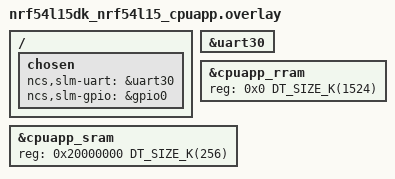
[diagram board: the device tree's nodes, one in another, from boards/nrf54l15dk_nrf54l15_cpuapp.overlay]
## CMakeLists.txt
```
#
# Copyright (c) 2020 Nordic Semiconductor ASA
#
# SPDX-License-Identifier: LicenseRef-Nordic-5-Clause
#
cmake_minimum_required(VERSION 3.20.0)

find_package(Zephyr REQUIRED HINTS $ENV{ZEPHYR_BASE})

project(openthread_cellular_mesh_meter)

# NORDIC SDK APP START
target_sources(app PRIVATE src/main.c
			   src/coap_utils.c)
# NORDIC SDK APP END

target_sources_ifdef(CONFIG_MODEM_UTILS_SIMULATED app PRIVATE src/modem_utils_simulated.c)
target_sources_ifdef(CONFIG_MODEM_UTILS_SERIAL_LTE_MODEM app PRIVATE src/modem_utils_slm.c)

target_sources_ifdef(CONFIG_BT_NUS app PRIVATE src/ble_utils.c)
```

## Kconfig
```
#
# Copyright (c) 2020 Nordic Semiconductor ASA
#
# SPDX-License-Identifier: LicenseRef-Nordic-5-Clause
#

menu "Zephyr Kernel"
source "Kconfig.zephyr"
endmenu

config MODEM_UTILS_SIMULATED
	bool "Simulated modem utilities"
	help
	  When enabled, the modem utilities will be simulated.

config MODEM_UTILS_SERIAL_LTE_MODEM
	bool "Serial LTE modem utilities"
	help
	  When enabled, the modem utilities will be using the serial LTE modem.

module = CELLULAR_MESH_METER
module-str = Cellular mesh meter
source "${ZEPHYR_BASE}/subsys/logging/Kconfig.template.log_config"

module = CELLULAR_MESH_METER_UTILS
module-str = Cellular mesh meter utilities
source "${ZEPHYR_BASE}/subsys/logging/Kconfig.template.log_config"

module = BLE_UTILS
module-str = Bluetooth connection utilities
source "${ZEPHYR_BASE}/subsys/logging/Kconfig.template.log_config"

module = MODEM_UTILS
module-str = Modem link utilities
source "${ZEPHYR_BASE}/subsys/logging/Kconfig.template.log_config"
```

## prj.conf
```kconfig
#
# Copyright (c) 2020 Nordic Semiconductor
#
# SPDX-License-Identifier: LicenseRef-Nordic-5-Clause
#

# nRF board library
CONFIG_DK_LIBRARY=y

# Enable CoAP utils and CoAP protocol
CONFIG_COAP=y
CONFIG_COAP_UTILS=y

# Generic networking options
CONFIG_NETWORKING=y

# L2 OpenThread enabling
CONFIG_NET_L2_OPENTHREAD=y

# Network shell
CONFIG_SHELL=y
CONFIG_OPENTHREAD_SHELL=y
CONFIG_SHELL_ARGC_MAX=26
CONFIG_SHELL_CMD_BUFF_SIZE=416

# Increase Settings storage size
CONFIG_PM_PARTITION_SIZE_SETTINGS_STORAGE=0x8000

# Network sockets
CONFIG_NET_SOCKETS=y
CONFIG_POSIX_API=y
CONFIG_NET_SOCKETS_POLL_MAX=4

# Same network Master Key for client and server
CONFIG_OPENTHREAD_NETWORKKEY="00:11:22:33:44:55:66:77:88:99:aa:bb:cc:dd:ee:ff"

CONFIG_MBEDTLS_SHA1_C=n
CONFIG_FPU=y

# Enable OpenThread CoAP support API
CONFIG_OPENTHREAD_COAP=y

CONFIG_SHELL_WILDCARD=n
CONFIG_SHELL_ARGC_MAX=40
CONFIG_SHELL_CMD_BUFF_SIZE=1024
CONFIG_SHELL_STACK_SIZE=2048

CONFIG_SERIAL=y
CONFIG_UART_ASYNC_API=y

CONFIG_MODEM_SLM=y
CONFIG_MODEM_SLM_SHELL=n

CONFIG_MODEM_UTILS_SERIAL_LTE_MODEM=y

CONFIG_OPENTHREAD_SOURCES=y
CONFIG_OPENTHREAD_COAP_BLOCK=y
CONFIG_OPENTHREAD_THREAD_STACK_SIZE=8192
```

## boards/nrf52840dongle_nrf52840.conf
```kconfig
#
# Copyright (c) 2024 Nordic Semiconductor
#
# SPDX-License-Identifier: LicenseRef-Nordic-5-Clause
#

CONFIG_SHELL_BACKEND_SERIAL_INIT_PRIORITY=51

CONFIG_USB_CDC_ACM_LOG_LEVEL_OFF=y

CONFIG_USB_DEVICE_MANUFACTURER="Nordic Semiconductor ASA"
CONFIG_USB_DEVICE_PRODUCT="Thread CLI"
CONFIG_USB_DEVICE_VID=0x1915
CONFIG_USB_DEVICE_PID=0x0000

# Enable resetting to Bootloader using GPIO
CONFIG_OPENTHREAD_PLATFORM_BOOTLOADER_MODE_GPIO=y

CONFIG_MODEM_SLM=n
CONFIG_MODEM_UTILS_SERIAL_LTE_MODEM=n
CONFIG_MODEM_UTILS_SIMULATED=y
```

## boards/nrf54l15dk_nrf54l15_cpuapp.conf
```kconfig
#
# Copyright (c) 2024 Nordic Semiconductor
#
# SPDX-License-Identifier: LicenseRef-Nordic-5-Clause
#

# Disable the unsupported driver
CONFIG_NRFX_UARTE0=n

# Increase Main and shell stack sizes to avoid stack overflow
# while using CRACEN
CONFIG_MAIN_STACK_SIZE=6144
CONFIG_SHELL_STACK_SIZE=5120

# Workaround required as Zephyr L2 implies usage of NVS backend for settings.
# It should be removed once the proper fix will be applied in Zephyr.
CONFIG_NVS=n
CONFIG_ZMS=y
CONFIG_SETTINGS_ZMS=y

CONFIG_NRFX_UARTE30=y
CONFIG_UART_30_INTERRUPT_DRIVEN=n
CONFIG_UART_30_ASYNC=y
CONFIG_MODEM_SLM_POWER_PIN=4
#CONFIG_MODEM_SLM_INDICATE_PIN=13
CONFIG_MODEM_SLM_SHELL=y
```

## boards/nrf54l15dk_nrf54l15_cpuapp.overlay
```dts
/*
 * Copyright (c) 2024 Nordic Semiconductor ASA
 *
 * SPDX-License-Identifier: LicenseRef-Nordic-5-Clause
 */

/ {
	chosen {
		ncs,slm-uart = &uart30;
		ncs,slm-gpio = &gpio0;
	};
};

&uart30 {
	status = "okay";
};

// restore full RRAM and SRAM space - by default some parts are dedicated to FLPR
&cpuapp_rram {
	reg = <0x0 DT_SIZE_K(1524)>;
};

&cpuapp_sram {
	reg = <0x20000000 DT_SIZE_K(256)>;
	ranges = <0x0 0x20000000  DT_SIZE_K(256)>;
};
```

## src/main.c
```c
/*
 * Copyright (c) 2020 Nordic Semiconductor ASA
 *
 * SPDX-License-Identifier: LicenseRef-Nordic-5-Clause
 */

#include <zephyr/kernel.h>
#include <dk_buttons_and_leds.h>
#include <zephyr/logging/log.h>
#include <ram_pwrdn.h>
#include <zephyr/device.h>
#include <zephyr/pm/device.h>

#include "coap_utils.h"
#include "modem_utils.h"

#if CONFIG_BT_NUS
#include "ble_utils.h"
#endif

#include <zephyr/drivers/uart.h>
#include <zephyr/usb/usb_device.h>

LOG_MODULE_REGISTER(cellular_mesh_meter, CONFIG_CELLULAR_MESH_METER_LOG_LEVEL);

#define OT_CONNECTION_LED	DK_LED1
#define BLE_CONNECTION_LED	DK_LED2
#define MODEM_IDLE_LED		DK_LED3
#define MODEM_BUSY_LED		DK_LED4

#define DEFAULT_MEASURE_CNT 10
#define MEASURE_BLOCK_SIZE 512
#define UPLOAD_MEASUREMENT_TIMEOUT		K_MSEC(100)
#define UPLOAD_MEASUREMENT_RETRY_LIMIT	100

static bool uploading_measurement = false;
static uint16_t uploading_measurement_retry_count = 0;
static struct k_work_delayable uploading_measurement_work;
static uint32_t max_block_count = DEFAULT_MEASURE_CNT;

#if CONFIG_BT_NUS

#define COMMAND_UPLOAD_MEASUREMENT  'u'
#define COMMAND_CHANGE_UPLOAD_COUNT 'c'

int upload_measurement(void);

static void on_nus_received(struct bt_conn *conn, const uint8_t *const data, uint16_t len)
{
	LOG_INF("Received data: %c", data[0]);

	switch (*data) {
	case COMMAND_UPLOAD_MEASUREMENT:
		upload_measurement();
		break;
	
	case COMMAND_CHANGE_UPLOAD_COUNT:
		if (len > 1) {
			max_block_count = atoi((const char *)&data[1]);
		} else {
			LOG_WRN("Invalid data length");
		}
		break;

	default:
		LOG_WRN("Received invalid data from NUS");
	}
}

static void on_ble_connect(struct k_work *item)
{
	ARG_UNUSED(item);

	dk_set_led_on(BLE_CONNECTION_LED);
}

static void on_ble_disconnect(struct k_work *item)
{
	ARG_UNUSED(item);

	dk_set_led_off(BLE_CONNECTION_LED);
}

#endif /* CONFIG_BT_NUS */

static void on_ot_connect(struct k_work *item)
{
	ARG_UNUSED(item);

	dk_set_led_on(OT_CONNECTION_LED);
}

static void on_ot_disconnect(struct k_work *item)
{
	ARG_UNUSED(item);

	dk_set_led_off(OT_CONNECTION_LED);
}

static void on_button_changed(uint32_t button_state, uint32_t has_changed)
{
	uint32_t buttons = button_state & has_changed;

	if (buttons & DK_BTN1_MSK) {
		upload_measurement();
	}

	if (buttons & DK_BTN2_MSK) {
	}

	if (buttons & DK_BTN3_MSK) {
	}

	if (buttons & DK_BTN4_MSK) {
	}
}

static void on_modem_request(otMessage *message, const otMessageInfo *message_info)
{
	uint8_t command;
	modem_state current_modem_state = MODEM_STATE_OFF, remote_modem_state = MODEM_STATE_OFF;

	current_modem_state = modem_get_state();

	if (otMessageRead(message, otMessageGetOffset(message), &command,
		sizeof(command)) != sizeof(command)) {
		LOG_ERR("Modem handler - Missing modem command");
	}

	char ip_addr_from[OT_IP6_ADDRESS_STRING_SIZE], ip_addr_to[OT_IP6_ADDRESS_STRING_SIZE];

	otIp6AddressToString(&(message_info->mPeerAddr), ip_addr_from, sizeof(ip_addr_from));
	otIp6AddressToString(&(message_info->mSockAddr), ip_addr_to, sizeof(ip_addr_to));

	LOG_HEXDUMP_INF(ip_addr_from, strlen(ip_addr_from), "coap request from ");
	LOG_HEXDUMP_INF(ip_addr_to, strlen(ip_addr_to), "coap request to ");
	LOG_INF("Got command: %d", command);

	switch (command) {
	case MODEM_COMMAND_DISCOVER:
		if ((current_modem_state == MODEM_STATE_IDLE ) || (current_modem_state == MODEM_STATE_BUSY)) {
			otMessageInfo report_state_message_info;
			memset(&report_state_message_info, 0, sizeof(report_state_message_info));
			report_state_message_info.mPeerAddr = message_info->mPeerAddr;
			report_state_message_info.mPeerPort = COAP_PORT;
			coap_utils_modem_report_state(&report_state_message_info, current_modem_state);
		} else {	//MODEM_STATE_OFF
			LOG_INF("Modem is off");
		}
		break;

	case MODEM_COMMAND_REPORT_STATE:
		if (otMessageRead(message, otMessageGetOffset(message) + sizeof(command),
			&remote_modem_state, sizeof(remote_modem_state)) != sizeof(remote_modem_state)) {
			LOG_ERR("Missing modem state of the remote modem");
		} else {
			LOG_INF("Remote modem state: %d", remote_modem_state);
			coap_utils_modem_report_state_response(message, message_info);
			if ((remote_modem_state == MODEM_STATE_IDLE) && (uploading_measurement == false)) {
				otMessageInfo upload_measurement_message_info;

				uploading_measurement = true;
				memset(&upload_measurement_message_info, 0, sizeof(upload_measurement_message_info));
				upload_measurement_message_info.mPeerAddr = message_info->mPeerAddr;
				upload_measurement_message_info.mPeerPort = COAP_PORT;
				coap_utils_modem_upload_measurement(&upload_measurement_message_info);
			}
		}
		break;

	case MODEM_COMMAND_UPLOAD_MEASUREMENT:
		LOG_INF("Receive Upload Measurement command");
		if (current_modem_state == MODEM_STATE_IDLE) {
			LOG_INF("Modem is idle, start uploading measurement");
			modem_set_state(MODEM_STATE_BUSY);
			coap_utils_send_response(message, message_info, OT_COAP_CODE_CHANGED);
		} else {
			LOG_INF("Modem is busy, wait for next round");
			coap_utils_send_response(message, message_info, OT_COAP_CODE_SERVICE_UNAVAILABLE);
		}
		break;

	default:
		break;
	}
}

static void on_meter_block_tx(void *context,
							  uint8_t *block,
							  uint32_t position,
							  uint16_t *block_length,
							  bool *more)
{
	static uint32_t block_count = 0;
	ARG_UNUSED(position);

	LOG_INF("send block: Num %i Len %i pos: %i", block_count, *block_length, position);
	/* Fill tx block with ascii 0 ~ 9 */
	for (uint16_t i = 0; i < *block_length; i++) {
		block[i] = 48 + i % 10;
	}
	LOG_HEXDUMP_INF(block, *block_length, "Sent block:");
	if (block_count == max_block_count - 1)
	{
		block_count = 0;
		*more     = false;
	}
	else
	{
		*more = true;
		block_count++;
	}
}

static otError on_meter_block_rx(void *context,
								 const uint8_t *block,
								 uint32_t position,
								 uint16_t block_length,
								 bool more,
								 uint32_t total_length)
{
	ARG_UNUSED(total_length);
	int ret;

	LOG_INF("received block: Num %i Len %i more: %d", position / block_length, block_length, more);
	LOG_HEXDUMP_INF(block, block_length, "Received block:");
	ret = modem_cloud_upload_data(block, (size_t)block_length);
	if (ret != 0) {
		if (ret == -EBUSY) {
			LOG_DBG("Modem is busy, wait for next round");
			return OT_ERROR_BUSY;
		} else if (ret == -ENOMEM) {
			LOG_ERR("No memory to upload data");
			return OT_ERROR_NO_BUFS;
		} else {
			LOG_ERR("Fail to upload data to cloud");
			return OT_ERROR_FAILED;
		}
	}
	if (more == false) {
		LOG_INF("Received all blocks");
		modem_set_state(MODEM_STATE_IDLE);
	}
	return OT_ERROR_NONE;
}

static void on_meter_response(void *context, otMessage *message, const otMessageInfo *message_info, otError error)
{
	if (error != OT_ERROR_NONE)
	{
		LOG_ERR("coap receive response error %d: %s", error, otThreadErrorToString(error));
	}
	/* Upload finiched */
	uploading_measurement = false;
	LOG_INF("Upload finished");
	return;
}

static void on_modem_state_change(modem_state state)
{
	dk_set_led_off(MODEM_IDLE_LED);
	dk_set_led_off(MODEM_BUSY_LED);

	switch (state) {
	case MODEM_STATE_IDLE:
		dk_set_led_on(MODEM_IDLE_LED);
		break;

	case MODEM_STATE_BUSY:
		dk_set_led_on(MODEM_BUSY_LED);
		break;
	default:
		break;
	}
}

void uploading_measurement_handler(struct k_work *work)
{
	static uint32_t block_count = 0;

	if (uploading_measurement) {
		uint8_t block[MEASURE_BLOCK_SIZE];
		int ret;

		/* Fill tx block with ascii 0 ~ 9 */
		for (uint16_t i = 0; i < MEASURE_BLOCK_SIZE; i++) {
			block[i] = 48 + i % 10;
		}
		ret = modem_cloud_upload_data(block, MEASURE_BLOCK_SIZE);
		if (ret != 0) {
			if (ret == -EBUSY) {
				uploading_measurement_retry_count++;
				if (uploading_measurement_retry_count > UPLOAD_MEASUREMENT_RETRY_LIMIT) {
					LOG_ERR("Retry limit reached");
					goto error;
				}
				LOG_DBG("Modem is busy, wait for next round");
				k_work_schedule(&uploading_measurement_work, UPLOAD_MEASUREMENT_TIMEOUT);
			} else if (ret == -ENOMEM) {
				LOG_ERR("No memory to upload data");
				goto error;
			} else {
				LOG_ERR("Fail to upload data to cloud");
				goto error;
			}
		} else {
			LOG_INF("Sent block: Num %i Len %i", block_count, MEASURE_BLOCK_SIZE);
			uploading_measurement_retry_count = 0;
			if (block_count == max_block_count - 1) {
				block_count = 0;
				uploading_measurement = false;
				modem_set_state(MODEM_STATE_IDLE);
			} else {
				block_count++;
				k_work_schedule(&uploading_measurement_work, UPLOAD_MEASUREMENT_TIMEOUT);
			}
		}
	}
	return;
error:
	block_count = 0;
	uploading_measurement = false;
	uploading_measurement_retry_count = 0;
	return;
}

int upload_measurement(void)
{
	if (uploading_measurement) {
		LOG_INF("Already uploading measurement");
		return -EBUSY;
	}

	if (modem_get_state() == MODEM_STATE_IDLE) {
		LOG_INF("Modem is idle, start uploading measurement");
		modem_set_state(MODEM_STATE_BUSY);
		uploading_measurement = true;
		k_work_schedule(&uploading_measurement_work, K_NO_WAIT);
	} else if (modem_get_state() == MODEM_STATE_BUSY) {
		LOG_INF("Modem is busy, wait for next round");
		return -EBUSY;
	} else {
		LOG_INF("Modem is off. Ask remote modem to upload measurement");
		coap_utils_modem_discover();
	}

	return 0;
}

int main(void)
{
	int ret;

	LOG_INF("Start Cellular Mesh Meter sample");

	if (IS_ENABLED(CONFIG_RAM_POWER_DOWN_LIBRARY)) {
		power_down_unused_ram();
	}

	ret = dk_buttons_init(on_button_changed);
	if (ret) {
		LOG_ERR("Cannot init buttons (error: %d)", ret);
		return 0;
	}

	ret = dk_leds_init();
	if (ret) {
		LOG_ERR("Cannot init leds, (error: %d)", ret);
		return 0;
	}

#if CONFIG_BT_NUS
	struct bt_nus_cb nus_clbs = {
		.received = on_nus_received,
		.sent = NULL,
	};

	ret = ble_utils_init(&nus_clbs, on_ble_connect, on_ble_disconnect);
	if (ret) {
		LOG_ERR("Cannot init BLE utilities");
		return 0;
	}

#endif /* CONFIG_BT_NUS */

#if DT_NODE_HAS_COMPAT(DT_CHOSEN(zephyr_shell_uart), zephyr_cdc_acm_uart)
	const struct device *dev;
	uint32_t dtr = 0U;

	ret = usb_enable(NULL);
	if (ret != 0 && ret != -EALREADY) {
		LOG_ERR("Failed to enable USB");
		return 0;
	}

	dev = DEVICE_DT_GET(DT_CHOSEN(zephyr_shell_uart));
	if (dev == NULL) {
		LOG_ERR("Failed to find specific UART device");
		return 0;
	}

	LOG_INF("Waiting for host to be ready to communicate");

	/* Data Terminal Ready - check if host is ready to communicate */
	while (!dtr) {
		ret = uart_line_ctrl_get(dev, UART_LINE_CTRL_DTR, &dtr);
		if (ret) {
			LOG_ERR("Failed to get Data Terminal Ready line state: %d",
				ret);
			continue;
		}
		k_msleep(100);
	}

	/* Data Carrier Detect Modem - mark connection as established */
	(void)uart_line_ctrl_set(dev, UART_LINE_CTRL_DCD, 1);
	/* Data Set Ready - the NCP SoC is ready to communicate */
	(void)uart_line_ctrl_set(dev, UART_LINE_CTRL_DSR, 1);
#endif

	k_work_init_delayable(&uploading_measurement_work, uploading_measurement_handler);

	ret = ot_coap_init(&on_modem_request, &on_meter_block_tx, &on_meter_block_rx, &on_meter_response);
	if (ret) {
		LOG_ERR("Could not initialize OpenThread CoAP");
	}
	coap_client_utils_init(on_ot_connect, on_ot_disconnect);

	ret = modem_init(on_modem_state_change);
	if (ret) {
		LOG_ERR("Cannot init modem (error: %d)", ret);
		return ret;
	}

	return 0;
}
```

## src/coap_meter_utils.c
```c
/*
 * Copyright (c) 2020 Nordic Semiconductor ASA
 *
 * SPDX-License-Identifier: LicenseRef-Nordic-5-Clause
 */

#include <zephyr/kernel.h>
#include <net/coap_utils.h>
#include <zephyr/logging/log.h>
#include <zephyr/net/openthread.h>
#include <zephyr/net/socket.h>

#include "coap_meter_utils.h"

LOG_MODULE_REGISTER(cellular_mesh_meter_util, CONFIG_CELLULAR_MESH_METER_UTILS_LOG_LEVEL);

#define RESPONSE_POLL_PERIOD 100

static uint32_t poll_period;

static bool is_connected;

#define COAP_WORKQ_STACK_SIZE 2048
#define COAP_WORKQ_PRIORITY 5

K_THREAD_STACK_DEFINE(coap_client_workq_stack_area, COAP_WORKQ_STACK_SIZE);
static struct k_work_q coap_client_workq;

static struct k_work toggle_MTD_SED_work;
static struct k_work modem_discover_work;
static struct k_work on_connect_work;
static struct k_work on_disconnect_work;

mtd_mode_toggle_cb_t on_mtd_mode_toggle;

/* Options supported by the server */
static const char *const modem_option[] = { MODEM_URI_PATH, NULL };
static const char *const provisioning_option[] = { PROVISIONING_URI_PATH,
						   NULL };

/* Thread multicast mesh local address */
static struct sockaddr_in6 multicast_local_addr = {
	.sin6_family = AF_INET6,
	.sin6_port = htons(COAP_PORT),
	.sin6_addr.s6_addr = { 0xff, 0x03, 0x00, 0x00, 0x00, 0x00, 0x00, 0x00,
			       0x00, 0x00, 0x00, 0x00, 0x00, 0x00, 0x00, 0x01 },
	.sin6_scope_id = 0U
};

/* Variable for storing server address acquiring in provisioning handshake */
static char unique_local_addr_str[INET6_ADDRSTRLEN];
static struct sockaddr_in6 unique_local_addr = {
	.sin6_family = AF_INET6,
	.sin6_port = htons(COAP_PORT),
	.sin6_addr.s6_addr = {0, },
	.sin6_scope_id = 0U
};

struct server_context {
	struct otInstance *ot;
	bool provisioning_enabled;
	modem_request_callback_t on_modem_request;
	provisioning_request_callback_t on_provisioning_request;
};

static struct server_context srv_context = {
	.ot = NULL,
	.provisioning_enabled = false,
	.on_modem_request = NULL,
	.on_provisioning_request = NULL,
};

/**@brief Definition of CoAP resources for provisioning. */
static otCoapResource provisioning_resource = {
	.mUriPath = PROVISIONING_URI_PATH,
	.mHandler = NULL,
	.mContext = NULL,
	.mNext = NULL,
};

/**@brief Definition of CoAP resources for modem. */
static otCoapResource modem_resource = {
	.mUriPath = MODEM_URI_PATH,
	.mHandler = NULL,
	.mContext = NULL,
	.mNext = NULL,
};

static otError provisioning_response_send(otMessage *request_message,
					  const otMessageInfo *message_info)
{
	otError error = OT_ERROR_NO_BUFS;
	otMessage *response;
	const void *payload;
	uint16_t payload_size;

	response = otCoapNewMessage(srv_context.ot, NULL);
	if (response == NULL) {
		goto end;
	}

	otCoapMessageInit(response, OT_COAP_TYPE_NON_CONFIRMABLE,
			  OT_COAP_CODE_CONTENT);

	error = otCoapMessageSetToken(
		response, otCoapMessageGetToken(request_message),
		otCoapMessageGetTokenLength(request_message));
	if (error != OT_ERROR_NONE) {
		goto end;
	}

	error = otCoapMessageSetPayloadMarker(response);
	if (error != OT_ERROR_NONE) {
		goto end;
	}

	payload = otThreadGetMeshLocalEid(srv_context.ot);
	payload_size = sizeof(otIp6Address);

	error = otMessageAppend(response, payload, payload_size);
	if (error != OT_ERROR_NONE) {
		goto end;
	}

	error = otCoapSendResponse(srv_context.ot, response, message_info);

	LOG_HEXDUMP_INF(payload, payload_size, "Sent provisioning response:");

end:
	if (error != OT_ERROR_NONE && response != NULL) {
		otMessageFree(response);
	}

	return error;
}

otError coap_server_send_modem_update_state_response(otMessage *request_message,
					  const otMessageInfo *message_info)
{
	otError error = OT_ERROR_NO_BUFS;
	otMessage *response;

	response = otCoapNewMessage(srv_context.ot, NULL);
	if (response == NULL) {
		goto end;
	}

	error = otCoapMessageInitResponse(response, request_message, OT_COAP_TYPE_ACKNOWLEDGMENT,
									  OT_COAP_CODE_CHANGED);
	if (error != OT_ERROR_NONE) {
		goto end;
	}

	error = otCoapSendResponse(srv_context.ot, response, message_info);

end:
	if (error != OT_ERROR_NONE && response != NULL) {
		otMessageFree(response);
	}

	return error;
}

void handle_modem_update_state_response(void *context, otMessage *message, const otMessageInfo *message_info, otError error)
{
	char string[OT_IP6_ADDRESS_STRING_SIZE], string2[OT_IP6_ADDRESS_STRING_SIZE];

	LOG_INF("Modem response received");

	otIp6AddressToString(&(message_info->mPeerAddr), string, sizeof(string));
	otIp6AddressToString(&(message_info->mSockAddr), string2, sizeof(string2));

	LOG_HEXDUMP_INF(string, strlen(string), "modem response from ");
	LOG_HEXDUMP_INF(string2, strlen(string2), "modem request to ");
}

otError coap_client_send_modem_update_state(const otMessageInfo *message_info,
					  uint8_t modem_state)
{
	otError error = OT_ERROR_NO_BUFS;
	otMessage *message;
	char uri[] = "modem";

	message = otCoapNewMessage(srv_context.ot, NULL);
	if (message == NULL) {
		goto end;
	}

	otCoapMessageInit(message, OT_COAP_TYPE_CONFIRMABLE,
			  OT_COAP_CODE_PUT);
	otCoapMessageGenerateToken(message, OT_COAP_DEFAULT_TOKEN_LENGTH);
	error = otCoapMessageAppendUriPathOptions(message, uri);
	if (error != OT_ERROR_NONE) {
		goto end;
	}

	error = otCoapMessageSetPayloadMarker(message);
	if (error != OT_ERROR_NONE) {
		goto end;
	}

	error = otMessageAppend(message, &modem_state, sizeof(modem_state));
	if (error != OT_ERROR_NONE) {
		goto end;
	}

	error = otCoapSendRequest(srv_context.ot, message, message_info, &handle_modem_update_state_response, NULL);
	LOG_INF("Sent modem state: %d", modem_state);

end:
	if (error != OT_ERROR_NONE && message != NULL) {
		LOG_ERR("Failed to send modem state: %d", error);
		otMessageFree(message);
	}

	return error;
}

static bool is_mtd_in_med_mode(otInstance *instance)
{
	return otThreadGetLinkMode(instance).mRxOnWhenIdle;
}

static void poll_period_response_set(void)
{
	otError error;

	otInstance *instance = openthread_get_default_instance();

	if (is_mtd_in_med_mode(instance)) {
		return;
	}

	if (!poll_period) {
		poll_period = otLinkGetPollPeriod(instance);

		error = otLinkSetPollPeriod(instance, RESPONSE_POLL_PERIOD);
		__ASSERT(error == OT_ERROR_NONE, "Failed to set pool period");

		LOG_INF("Poll Period: %dms set", RESPONSE_POLL_PERIOD);
	}
}

static void poll_period_restore(void)
{
	otError error;
	otInstance *instance = openthread_get_default_instance();

	if (is_mtd_in_med_mode(instance)) {
		return;
	}

	if (poll_period) {
		error = otLinkSetPollPeriod(instance, poll_period);
		__ASSERT_NO_MSG(error == OT_ERROR_NONE);

		LOG_INF("Poll Period: %dms restored", poll_period);
		poll_period = 0;
	}
}

static void send_modem_discover_request(struct k_work *item)
{
	ARG_UNUSED(item);
	uint8_t command = (uint8_t)THREAD_COAP_UTILS_MODEM_CMD_DISCOVER;

	if (IS_ENABLED(CONFIG_OPENTHREAD_MTD_SED)) {
		/* decrease the polling period for higher responsiveness */
		poll_period_response_set();
	}

	LOG_INF("Send 'discover' request");
	coap_send_request(COAP_METHOD_PUT,
			  (const struct sockaddr *)&multicast_local_addr,
			  modem_option, &command, sizeof(command), NULL);
}

static void toggle_minimal_sleepy_end_device(struct k_work *item)
{
	otError error;
	otLinkModeConfig mode;
	struct openthread_context *context = openthread_get_default_context();

	__ASSERT_NO_MSG(context != NULL);

	openthread_api_mutex_lock(context);
	mode = otThreadGetLinkMode(context->instance);
	mode.mRxOnWhenIdle = !mode.mRxOnWhenIdle;
	error = otThreadSetLinkMode(context->instance, mode);
	openthread_api_mutex_unlock(context);

	if (error != OT_ERROR_NONE) {
		LOG_ERR("Failed to set MLE link mode configuration");
	} else {
		on_mtd_mode_toggle(mode.mRxOnWhenIdle);
	}
}

static void update_device_state(void)
{
	struct otInstance *instance = openthread_get_default_instance();
	otLinkModeConfig mode = otThreadGetLinkMode(instance);
	on_mtd_mode_toggle(mode.mRxOnWhenIdle);
}

static void on_thread_state_changed(otChangedFlags flags, struct openthread_context *ot_context,
				    void *user_data)
{
	if (flags & OT_CHANGED_THREAD_ROLE) {
		switch (otThreadGetDeviceRole(ot_context->instance)) {
		case OT_DEVICE_ROLE_CHILD:
		case OT_DEVICE_ROLE_ROUTER:
		case OT_DEVICE_ROLE_LEADER:
			k_work_submit_to_queue(&coap_client_workq, &on_connect_work);
			is_connected = true;
			break;

		case OT_DEVICE_ROLE_DISABLED:
		case OT_DEVICE_ROLE_DETACHED:
		default:
			k_work_submit_to_queue(&coap_client_workq, &on_disconnect_work);
			is_connected = false;
			break;
		}
	}
}
static struct openthread_state_changed_cb ot_state_chaged_cb = {
	.state_changed_cb = on_thread_state_changed
};

static void submit_work_if_connected(struct k_work *work)
{
	if (is_connected) {
		k_work_submit_to_queue(&coap_client_workq, work);
	} else {
		LOG_INF("Connection is broken");
	}
}

void coap_client_utils_init(ot_connection_cb_t on_connect,
			    ot_disconnection_cb_t on_disconnect,
			    mtd_mode_toggle_cb_t on_toggle)
{
	on_mtd_mode_toggle = on_toggle;

	coap_init(AF_INET6, NULL);


	k_work_queue_init(&coap_client_workq);

	k_work_queue_start(&coap_client_workq, coap_client_workq_stack_area,
					K_THREAD_STACK_SIZEOF(coap_client_workq_stack_area),
					COAP_WORKQ_PRIORITY, NULL);

	k_work_init(&on_connect_work, on_connect);
	k_work_init(&on_disconnect_work, on_disconnect);
	k_work_init(&modem_discover_work, send_modem_discover_request);

	openthread_state_changed_cb_register(openthread_get_default_context(), &ot_state_chaged_cb);
	openthread_start(openthread_get_default_context());

	if (IS_ENABLED(CONFIG_OPENTHREAD_MTD_SED)) {
		k_work_init(&toggle_MTD_SED_work,
			    toggle_minimal_sleepy_end_device);
		update_device_state();
	}
}

void coap_client_send_modem_discover_request(void)
{
	submit_work_if_connected(&modem_discover_work);
}

void coap_client_toggle_minimal_sleepy_end_device(void)
{
	if (IS_ENABLED(CONFIG_OPENTHREAD_MTD_SED)) {
		k_work_submit_to_queue(&coap_client_workq, &toggle_MTD_SED_work);
	}
}

static void provisioning_request_handler(void *context, otMessage *message,
					 const otMessageInfo *message_info)
{
	otError error;
	otMessageInfo msg_info;

	ARG_UNUSED(context);
#if 0
	if (!srv_context.provisioning_enabled) {
		LOG_WRN("Received provisioning request but provisioning "
			"is disabled");
		return;
	}
#endif
	LOG_INF("Received provisioning request");

	if ((otCoapMessageGetType(message) == OT_COAP_TYPE_NON_CONFIRMABLE) &&
	    (otCoapMessageGetCode(message) == OT_COAP_CODE_GET)) {
		msg_info = *message_info;
		memset(&msg_info.mSockAddr, 0, sizeof(msg_info.mSockAddr));

		srv_context.on_provisioning_request();

		error = provisioning_response_send(message, &msg_info);
		if (error == OT_ERROR_NONE) {
			//srv_context.on_provisioning_request();
			srv_context.provisioning_enabled = false;
		}
	}
}

static void modem_request_handler(void *context, otMessage *message,
				  const otMessageInfo *message_info)
{
	ARG_UNUSED(context);
	static uint16_t message_id;

	if (otIp6IsAddressEqual(&(message_info->mPeerAddr), otThreadGetMeshLocalEid(srv_context.ot))) {
		LOG_WRN("Received message from itself");
		return;
	}

	if (otCoapMessageGetMessageId(message) == message_id) {
		LOG_WRN("Received the same message id");
		return;
	}
	message_id = otCoapMessageGetMessageId(message);

	if (otCoapMessageGetCode(message) != OT_COAP_CODE_PUT) {
		LOG_ERR("Modem handler - Unexpected CoAP code");
		return;
	}

	srv_context.on_modem_request(message, message_info);
}

static void coap_default_handler(void *context, otMessage *message,
				 const otMessageInfo *message_info)
{
	ARG_UNUSED(context);
	ARG_UNUSED(message);
	ARG_UNUSED(message_info);

	LOG_INF("Received CoAP message that does not match any request "
		"or resource");
}

int ot_coap_init(provisioning_request_callback_t on_provisioning_request,
                 modem_request_callback_t on_modem_request)
{
	otError error;

	srv_context.provisioning_enabled = true;
	srv_context.on_provisioning_request = on_provisioning_request;
	srv_context.on_modem_request = on_modem_request;

	srv_context.ot = openthread_get_default_instance();
	if (!srv_context.ot) {
		LOG_ERR("There is no valid OpenThread instance");
		error = OT_ERROR_FAILED;
		goto end;
	}

	provisioning_resource.mContext = srv_context.ot;
	provisioning_resource.mHandler = provisioning_request_handler;

	modem_resource.mContext = srv_context.ot;
	modem_resource.mHandler = modem_request_handler;

	otCoapSetDefaultHandler(srv_context.ot, coap_default_handler, NULL);
	otCoapAddResource(srv_context.ot, &modem_resource);
	otCoapAddResource(srv_context.ot, &provisioning_resource);

	error = otCoapStart(srv_context.ot, COAP_PORT);
	if (error != OT_ERROR_NONE) {
		LOG_ERR("Failed to start OT CoAP. Error: %d", error);
		goto end;
	}

end:
	return error == OT_ERROR_NONE ? 0 : 1;
}
```

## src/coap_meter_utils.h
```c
/**
 * @file
 * @defgroup coap_client_utils API for coap_client_* samples
 * @{
 */

/*
 * Copyright (c) 2020 Nordic Semiconductor ASA
 *
 * SPDX-License-Identifier: LicenseRef-Nordic-5-Clause
 */

#ifndef __COAP_METER_UTILS_H__
#define __COAP_METER_UTILS_H__

#include <openthread/coap.h>
#include <openthread/ip6.h>
#include <openthread/message.h>
#include <openthread/thread.h>

/** @brief Type indicates function called when OpenThread connection
 *         is established.
 *
 * @param[in] item pointer to work item.
 */
typedef void (*ot_connection_cb_t)(struct k_work *item);

/** @brief Type indicates function called when OpenThread connection is ended.
 *
 * @param[in] item pointer to work item.
 */
typedef void (*ot_disconnection_cb_t)(struct k_work *item);

/** @brief Type indicates function called when the MTD modes are toggled.
 *
 * @param[in] val 1 if the MTD is in MED mode
 *                0 if the MTD is in SED mode
 */
typedef void (*mtd_mode_toggle_cb_t)(uint32_t val);

/** @brief Initialize CoAP client utilities.
 */
void coap_client_utils_init(ot_connection_cb_t on_connect,
			    ot_disconnection_cb_t on_disconnect,
				mtd_mode_toggle_cb_t on_toggle);

/**
 * @brief Send CoAP request to update modem state.
 */
otError coap_client_send_modem_update_state(const otMessageInfo *message_info,
					  uint8_t modem_state);

/**
 * @brief Send CoAP response to modem update state request.
 */
otError coap_server_send_modem_update_state_response(otMessage *request_message,
					  const otMessageInfo *message_info);

/** @brief Multicast request to discover available modems.
 *
 * @note CoAP server with available modem will send Update State request back.
 */
void coap_client_send_modem_discover_request(void);

/** @brief Toggle SED to MED and MED to SED modes.
 *
 * @note Active when the device is working as Minimal Thread Device.
 */
void coap_client_toggle_minimal_sleepy_end_device(void);

#define COAP_PORT OT_DEFAULT_COAP_PORT
#define PROVISIONING_URI_PATH "provisioning"
#define MODEM_URI_PATH "modem"

/**@brief Enumeration describing modem commands. */
enum modem_command {
	THREAD_COAP_UTILS_MODEM_CMD_DISCOVER,
	THREAD_COAP_UTILS_MODEM_CMD_UPDATE_STATE_IDLE,
	THREAD_COAP_UTILS_MODEM_CMD_UPDATE_STATE_BUSY
};

typedef void (*modem_request_callback_t)(otMessage *message,
				  const otMessageInfo *message_info);
typedef void (*provisioning_request_callback_t)();

int ot_coap_init(provisioning_request_callback_t on_provisioning_request,
                 modem_request_callback_t on_modem_request);

#endif

/**
 * @}
 */
```

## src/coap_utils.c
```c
/*
 * Copyright (c) 2020 Nordic Semiconductor ASA
 *
 * SPDX-License-Identifier: LicenseRef-Nordic-5-Clause
 */

#include <stdlib.h>
#include <zephyr/kernel.h>
#include <net/coap_utils.h>
#include <zephyr/logging/log.h>
#include <zephyr/net/openthread.h>
#include <zephyr/net/socket.h>

#include "coap_utils.h"

LOG_MODULE_REGISTER(cellular_mesh_meter_util, CONFIG_CELLULAR_MESH_METER_UTILS_LOG_LEVEL);

static bool is_connected;

#define COAP_WORKQ_STACK_SIZE 2048
#define COAP_WORKQ_PRIORITY 5

K_THREAD_STACK_DEFINE(coap_client_workq_stack_area, COAP_WORKQ_STACK_SIZE);
static struct k_work_q coap_client_workq;

static struct k_work modem_discover_work;
static struct k_work meter_upload_work;
static struct k_work on_connect_work;
static struct k_work on_disconnect_work;

/* Variable for storing peer address acquiring in modem upload measurement handshake */
static otIp6Address metter_peer_address;

struct server_context {
	struct otInstance *ot;
	modem_request_callback_t on_modem_request;
	meter_block_tx_callback_t on_meter_block_tx;
	meter_block_rx_callback_t on_meter_block_rx;
	meter_response_callback_t on_meter_response;
};

static struct server_context srv_context = {
	.ot = NULL,
	.on_modem_request = NULL,
	.on_meter_block_tx = NULL,
	.on_meter_block_rx = NULL,
	.on_meter_response = NULL,
};

/**@brief Definition of CoAP block resources for meter. */
static otCoapBlockwiseResource meter_resource = {
	.mUriPath = METER_URI_PATH,
	.mHandler = NULL,
	.mContext = NULL,
	.mReceiveHook = NULL,
	.mTransmitHook = NULL,
	.mNext = NULL,
};

/**@brief Definition of CoAP resources for modem. */
static otCoapResource modem_resource = {
	.mUriPath = MODEM_URI_PATH,
	.mHandler = NULL,
	.mContext = NULL,
	.mNext = NULL,
};

static void submit_work_if_connected(struct k_work *work);

otError coap_utils_modem_report_state_response(otMessage *request_message,
					  const otMessageInfo *message_info)
{
	otError error = OT_ERROR_NO_BUFS;
	otMessage *response;

	response = otCoapNewMessage(srv_context.ot, NULL);
	if (response == NULL) {
		goto end;
	}

	error = otCoapMessageInitResponse(response, request_message, OT_COAP_TYPE_ACKNOWLEDGMENT,
									  OT_COAP_CODE_CHANGED);
	if (error != OT_ERROR_NONE) {
		goto end;
	}

	error = otCoapSendResponse(srv_context.ot, response, message_info);

end:
	if (error != OT_ERROR_NONE && response != NULL) {
		otMessageFree(response);
	}

	return error;
}

otError coap_utils_send_response(otMessage *request_message,
								 const otMessageInfo *message_info,
								 otCoapCode code)
{
	otError error = OT_ERROR_NO_BUFS;
	otMessage *response;

	response = otCoapNewMessage(srv_context.ot, NULL);
	if (response == NULL) {
		goto end;
	}

	error = otCoapMessageInitResponse(response, request_message, OT_COAP_TYPE_ACKNOWLEDGMENT,
									  code);
	if (error != OT_ERROR_NONE) {
		goto end;
	}

	error = otCoapSendResponse(srv_context.ot, response, message_info);
end:
	if (error != OT_ERROR_NONE && response != NULL) {
		otMessageFree(response);
	}

	return error;
}

static void handle_report_state_response(void *context, otMessage *message, const otMessageInfo *message_info, otError error)
{
    if (error != OT_ERROR_NONE)
    {
        LOG_ERR("report state request error %d: %s", error, otThreadErrorToString(error));
    } else if ((message_info != NULL) && (message != NULL)) {
		LOG_INF("report state response from ");
		LOG_HEXDUMP_INF(message_info->mPeerAddr.mFields.m8, sizeof(message_info->mPeerAddr.mFields.m8), "peer address:");
	}
}

static void handle_upload_measurement_response(void *context, otMessage *message, const otMessageInfo *message_info, otError error)
{
    if (error != OT_ERROR_NONE)
    {
        LOG_ERR("report state request error %d: %s", error, otThreadErrorToString(error));
    } else if ((message_info != NULL) && (message != NULL)) {
		LOG_INF("upload measurement response from ");
		LOG_HEXDUMP_INF(message_info->mPeerAddr.mFields.m8, sizeof(message_info->mPeerAddr.mFields.m8), "peer address:");
		if (otCoapMessageGetCode(message) == OT_COAP_CODE_CHANGED) {
			LOG_INF("Modem upload measurement success");
			metter_peer_address = message_info->mPeerAddr;
			submit_work_if_connected(&meter_upload_work);
		} else if (otCoapMessageGetCode(message) == OT_COAP_CODE_SERVICE_UNAVAILABLE) {
			LOG_INF("Modem is busy, wait for next round");
		} else {
			LOG_ERR("Modem upload measurement failed");
		}
	}
}

otError coap_utils_modem_upload_measurement(const otMessageInfo *message_info)
{
	otError error = OT_ERROR_NO_BUFS;
	otMessage *message;
	char uri[] = "modem";
	uint8_t modem_command = MODEM_COMMAND_UPLOAD_MEASUREMENT;

	message = otCoapNewMessage(srv_context.ot, NULL);
	if (message == NULL) {
		goto end;
	}

	otCoapMessageInit(message, OT_COAP_TYPE_CONFIRMABLE,
			  OT_COAP_CODE_PUT);
	otCoapMessageGenerateToken(message, OT_COAP_DEFAULT_TOKEN_LENGTH);
	error = otCoapMessageAppendUriPathOptions(message, uri);
	if (error != OT_ERROR_NONE) {
		goto end;
	}

	error = otCoapMessageSetPayloadMarker(message);
	if (error != OT_ERROR_NONE) {
		goto end;
	}

	error = otMessageAppend(message, &modem_command, sizeof(modem_command));
	if (error != OT_ERROR_NONE) {
		goto end;
	}

	error = otCoapSendRequest(srv_context.ot, message, message_info, &handle_upload_measurement_response, NULL);
	LOG_INF("Sent modem upload measurement");

end:
	if (error != OT_ERROR_NONE && message != NULL) {
		LOG_ERR("Failed to send modem upload measurement: %d", error);
		otMessageFree(message);
	}

	return error;
}

otError coap_utils_modem_report_state(const otMessageInfo *message_info,
					  uint8_t modem_state)
{
	otError error = OT_ERROR_NO_BUFS;
	otMessage *message;
	char uri[] = "modem";
	uint8_t modem_command = MODEM_COMMAND_REPORT_STATE;

	message = otCoapNewMessage(srv_context.ot, NULL);
	if (message == NULL) {
		goto end;
	}

	otCoapMessageInit(message, OT_COAP_TYPE_CONFIRMABLE,
			  OT_COAP_CODE_PUT);
	otCoapMessageGenerateToken(message, OT_COAP_DEFAULT_TOKEN_LENGTH);
	error = otCoapMessageAppendUriPathOptions(message, uri);
	if (error != OT_ERROR_NONE) {
		goto end;
	}

	error = otCoapMessageSetPayloadMarker(message);
	if (error != OT_ERROR_NONE) {
		goto end;
	}

	error = otMessageAppend(message, &modem_command, sizeof(modem_command));
	if (error != OT_ERROR_NONE) {
		goto end;
	}

	error = otMessageAppend(message, &modem_state, sizeof(modem_state));
	if (error != OT_ERROR_NONE) {
		goto end;
	}

	error = otCoapSendRequest(srv_context.ot, message, message_info, &handle_report_state_response, NULL);
	LOG_INF("Sent modem state: %d", modem_state);

end:
	if (error != OT_ERROR_NONE && message != NULL) {
		LOG_ERR("Failed to send modem state: %d", error);
		otMessageFree(message);
	}

	return error;
}

static void send_modem_discover_request(struct k_work *item)
{
	ARG_UNUSED(item);
	uint8_t command = (uint8_t)MODEM_COMMAND_DISCOVER;

	otError error = OT_ERROR_NO_BUFS;
	otMessage *message;
	char uri[] = "modem";
	char multicast_address[] = "ff03::01";
	otMessageInfo message_info;

	message = otCoapNewMessage(srv_context.ot, NULL);
	if (message == NULL) {
		goto end;
	}

	otCoapMessageInit(message, OT_COAP_TYPE_NON_CONFIRMABLE, OT_COAP_CODE_PUT);
	otCoapMessageGenerateToken(message, OT_COAP_DEFAULT_TOKEN_LENGTH);
	error = otCoapMessageAppendUriPathOptions(message, uri);
	if (error != OT_ERROR_NONE) {
		goto end;
	}

	error = otCoapMessageSetPayloadMarker(message);
	if (error != OT_ERROR_NONE) {
		goto end;
	}

	error = otMessageAppend(message, &command, sizeof(command));
	if (error != OT_ERROR_NONE) {
		goto end;
	}

	memset(&message_info, 0, sizeof(message_info));
	error = otIp6AddressFromString(multicast_address, &message_info.mPeerAddr);
	if (error != OT_ERROR_NONE) {
		goto end;
	}
	message_info.mPeerPort = COAP_PORT;
	message_info.mMulticastLoop = false;

	error = otCoapSendRequest(srv_context.ot, message, &message_info, NULL, NULL);
	LOG_INF("Sent modem state discover to address: %s", multicast_address);

end:
	if (error != OT_ERROR_NONE && message != NULL) {
		LOG_ERR("Failed to send modem state: %d", error);
		otMessageFree(message);
	}

	return;
}

static void meter_response_handler(void *context, otMessage *message, const otMessageInfo *message_info, otError error)
{
	srv_context.on_meter_response(context, message, message_info, error);
}

otError meter_block_tx_hook(void *context,
							uint8_t *block,
							uint32_t position,
							uint16_t *block_length,
							bool *more)
{
	srv_context.on_meter_block_tx(context, block, position, block_length, more);
	return OT_ERROR_NONE;
}

static otError meter_block_rx_hook(void *context,
								   const uint8_t *block,
								   uint32_t position,
								   uint16_t block_length,
								   bool more,
								   uint32_t total_length)
{
	return srv_context.on_meter_block_rx(context, block, position, block_length, more, total_length);
}

static void send_meter_upload_request(struct k_work *item)
{
	ARG_UNUSED(item);
	otError error = OT_ERROR_NO_BUFS;
	otMessage *message;
	otMessageInfo message_info;
	char uri[] = "meter";

	message = otCoapNewMessage(srv_context.ot, NULL);
	if (message == NULL) {
		goto end;
	}
	otCoapMessageInit(message, OT_COAP_TYPE_CONFIRMABLE, OT_COAP_CODE_PUT);
	otCoapMessageGenerateToken(message, OT_COAP_DEFAULT_TOKEN_LENGTH);
	error = otCoapMessageAppendUriPathOptions(message, uri);
	if (error != OT_ERROR_NONE) {
		goto end;
	}
	error = otCoapMessageAppendBlock1Option(message, 0, true, OT_COAP_OPTION_BLOCK_SZX_512);
	if (error != OT_ERROR_NONE) {
		goto end;
	}
	memset(&message_info, 0, sizeof(message_info));
    message_info.mPeerAddr = metter_peer_address;
    message_info.mPeerPort = COAP_PORT;
	error = otCoapMessageSetPayloadMarker(message);
	if (error != OT_ERROR_NONE) {
		goto end;
	}
	error = otCoapSendRequestBlockWise(srv_context.ot, message, &message_info,
									  &meter_response_handler, NULL,
									  &meter_block_tx_hook, &meter_block_rx_hook);
	if (error != OT_ERROR_NONE) {
		goto end;
	}
end:
	if (error != OT_ERROR_NONE && message != NULL) {
		LOG_ERR("Failed to send meter upload request: %d", error);
		otMessageFree(message);
	};
}

static void on_thread_state_changed(otChangedFlags flags, struct openthread_context *ot_context,
				    void *user_data)
{
	if (flags & OT_CHANGED_THREAD_ROLE) {
		switch (otThreadGetDeviceRole(ot_context->instance)) {
		case OT_DEVICE_ROLE_CHILD:
		case OT_DEVICE_ROLE_ROUTER:
		case OT_DEVICE_ROLE_LEADER:
			k_work_submit_to_queue(&coap_client_workq, &on_connect_work);
			is_connected = true;
			break;

		case OT_DEVICE_ROLE_DISABLED:
		case OT_DEVICE_ROLE_DETACHED:
		default:
			k_work_submit_to_queue(&coap_client_workq, &on_disconnect_work);
			is_connected = false;
			break;
		}
	}
}
static struct openthread_state_changed_cb ot_state_chaged_cb = {
	.state_changed_cb = on_thread_state_changed
};

static void submit_work_if_connected(struct k_work *work)
{
	if (is_connected) {
		k_work_submit_to_queue(&coap_client_workq, work);
	} else {
		LOG_INF("Connection is broken");
	}
}

void coap_client_utils_init(ot_connection_cb_t on_connect,
			    ot_disconnection_cb_t on_disconnect)
{
	coap_init(AF_INET6, NULL);


	k_work_queue_init(&coap_client_workq);

	k_work_queue_start(&coap_client_workq, coap_client_workq_stack_area,
					K_THREAD_STACK_SIZEOF(coap_client_workq_stack_area),
					COAP_WORKQ_PRIORITY, NULL);

	k_work_init(&on_connect_work, on_connect);
	k_work_init(&on_disconnect_work, on_disconnect);
	k_work_init(&modem_discover_work, send_modem_discover_request);
	k_work_init(&meter_upload_work, send_meter_upload_request);

	openthread_state_changed_cb_register(openthread_get_default_context(), &ot_state_chaged_cb);
	openthread_start(openthread_get_default_context());
}

void coap_utils_modem_discover(void)
{
	submit_work_if_connected(&modem_discover_work);
}

static void meter_request_handler(void *context, otMessage *message,
								  const otMessageInfo *message_info)
{
	ARG_UNUSED(context);

	if (otCoapMessageGetCode(message) != OT_COAP_CODE_PUT) {
		LOG_ERR("Meter handler - Unexpected CoAP code");
		return;
	}
	LOG_INF("meter request from");
	LOG_HEXDUMP_INF(message_info->mPeerAddr.mFields.m8, sizeof(message_info->mPeerAddr.mFields.m8), "peer address:");

	if (otCoapMessageGetType(message) == OT_COAP_TYPE_CONFIRMABLE) {
		coap_utils_send_response(message, message_info, OT_COAP_CODE_CHANGED);
	}
}

static void modem_request_handler(void *context, otMessage *message,
				  const otMessageInfo *message_info)
{
	ARG_UNUSED(context);
	static uint16_t message_id;

	if (otIp6IsAddressEqual(&(message_info->mPeerAddr), otThreadGetMeshLocalEid(srv_context.ot))) {
		LOG_WRN("Received message from itself");
		return;
	}

	if (otCoapMessageGetMessageId(message) == message_id) {
		LOG_WRN("Received the same message id");
		return;
	}
	message_id = otCoapMessageGetMessageId(message);

	if (otCoapMessageGetCode(message) != OT_COAP_CODE_PUT) {
		LOG_ERR("Modem handler - Unexpected CoAP code");
		return;
	}

	srv_context.on_modem_request(message, message_info);
}

static void coap_default_handler(void *context, otMessage *message,
				 const otMessageInfo *message_info)
{
	ARG_UNUSED(context);
	ARG_UNUSED(message);
	ARG_UNUSED(message_info);

	LOG_INF("Received CoAP message that does not match any request "
		"or resource");
}

int ot_coap_init(modem_request_callback_t on_modem_request,
				 meter_block_tx_callback_t on_meter_block_tx,
				 meter_block_rx_callback_t on_meter_block_rx,
				 meter_response_callback_t on_meter_response)
{
	otError error;

	srv_context.on_modem_request = on_modem_request;
	srv_context.on_meter_block_tx = on_meter_block_tx;
	srv_context.on_meter_block_rx = on_meter_block_rx;
	srv_context.on_meter_response = on_meter_response;

	srv_context.ot = openthread_get_default_instance();
	if (!srv_context.ot) {
		LOG_ERR("There is no valid OpenThread instance");
		error = OT_ERROR_FAILED;
		goto end;
	}

	meter_resource.mContext = srv_context.ot;
	meter_resource.mHandler = meter_request_handler;
	meter_resource.mReceiveHook = &meter_block_rx_hook;
	meter_resource.mTransmitHook = &meter_block_tx_hook;

	modem_resource.mContext = srv_context.ot;
	modem_resource.mHandler = modem_request_handler;

	otCoapSetDefaultHandler(srv_context.ot, coap_default_handler, NULL);
	otCoapAddResource(srv_context.ot, &modem_resource);
	otCoapAddBlockWiseResource(srv_context.ot, &meter_resource);

	error = otCoapStart(srv_context.ot, COAP_PORT);
	if (error != OT_ERROR_NONE) {
		LOG_ERR("Failed to start OT CoAP. Error: %d", error);
		goto end;
	}

end:
	return error == OT_ERROR_NONE ? 0 : 1;
}
```

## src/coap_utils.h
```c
/**
 * @file
 * @defgroup coap_client_utils API for coap_client_* samples
 * @{
 */

/*
 * Copyright (c) 2020 Nordic Semiconductor ASA
 *
 * SPDX-License-Identifier: LicenseRef-Nordic-5-Clause
 */

#ifndef __COAP_METER_UTILS_H__
#define __COAP_METER_UTILS_H__

#include <openthread/coap.h>
#include <openthread/ip6.h>
#include <openthread/message.h>
#include <openthread/thread.h>

#define COAP_PORT OT_DEFAULT_COAP_PORT
#define METER_URI_PATH "meter"
#define MODEM_URI_PATH "modem"

/**@brief Enumeration describing modem commands. */
enum modem_command {
	MODEM_COMMAND_DISCOVER,
	MODEM_COMMAND_REPORT_STATE,
	MODEM_COMMAND_UPLOAD_MEASUREMENT,
};

/** @brief Type indicates function called when OpenThread connection
 *         is established.
 *
 * @param[in] item pointer to work item.
 */
typedef void (*ot_connection_cb_t)(struct k_work *item);

/** @brief Type indicates function called when OpenThread connection is ended.
 *
 * @param[in] item pointer to work item.
 */
typedef void (*ot_disconnection_cb_t)(struct k_work *item);

/** @brief Initialize CoAP client utilities.
 */
void coap_client_utils_init(ot_connection_cb_t on_connect,
			    			ot_disconnection_cb_t on_disconnect);

/** @brief Send CoAP Multicast request to discover available modems.
 *
 * @note CoAP server with available modem will send report state back.
 */
void coap_utils_modem_discover(void);

/**
 * @brief Send CoAP request to report current modem state.
 */
otError coap_utils_modem_report_state(const otMessageInfo *message_info,
									  uint8_t modem_state);

/**
 * @brief Send CoAP response to modem report state request.
 */
otError coap_utils_modem_report_state_response(otMessage *request_message,
											   const otMessageInfo *message_info);

/**
 * @brief Send CoAP request to upload measurement to the remote modem.
 */
otError coap_utils_modem_upload_measurement(const otMessageInfo *message_info);

/**
 * @brief Send CoAP response with given response code.
 */
otError coap_utils_send_response(otMessage *request_message,
								 const otMessageInfo *message_info,
								 otCoapCode code);

/**
 * @brief Callback function for modem request.
 */
typedef void (*modem_request_callback_t)(otMessage *message,
										 const otMessageInfo *message_info);

/**
 * @brief Callback function for meter block transmission.
 */
typedef void (*meter_block_tx_callback_t)(void     *aContext,
										  uint8_t  *aBlock,
										  uint32_t  aPosition,
										  uint16_t *aBlockLength,
										  bool     *aMore);

/**
 * @brief Callback function for meter block reception.
 */
typedef otError (*meter_block_rx_callback_t)(void *aContext,
											 const uint8_t *aBlock,
											 uint32_t aPosition,
											 uint16_t aBlockLength,
											 bool aMore,
											 uint32_t aTotalLength);

/**
 * @brief Callback function for meter response.
 */
typedef void (*meter_response_callback_t)(void *context, otMessage *message, const otMessageInfo *message_info, otError error);

/**
 * @brief Initialize CoAP server utilities.
 */
int ot_coap_init(modem_request_callback_t on_modem_request,
				 meter_block_tx_callback_t on_meter_block_tx,
				 meter_block_rx_callback_t on_meter_block_rx,
				 meter_response_callback_t on_meter_response);

#endif

/**
 * @}
 */
```

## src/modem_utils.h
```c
#ifndef __MODEM_UTILS_H__
#define __MODEM_UTILS_H__

/**@brief Enumeration describing modem state. */
typedef enum {
	MODEM_STATE_UNKNOWN,
	MODEM_STATE_OFF,
	MODEM_STATE_IDLE,
	MODEM_STATE_BUSY
} modem_state;

typedef void (*modem_utils_state_handler_t)(modem_state state);

/**
 * @brief Initialize modem.
 */
int modem_init(modem_utils_state_handler_t handler);

/**
 * @brief Get modem state.
 */
modem_state modem_get_state(void);

/**
 * @brief Set modem state.
 */
void modem_set_state(modem_state);

/**
 * @brief Initialize modem cloud connection.
 */
int modem_cloud_connect(void);

int modem_cloud_upload_data(const uint8_t *data, size_t size);

#endif /* __MODEM_UTILS_H__ */
```
